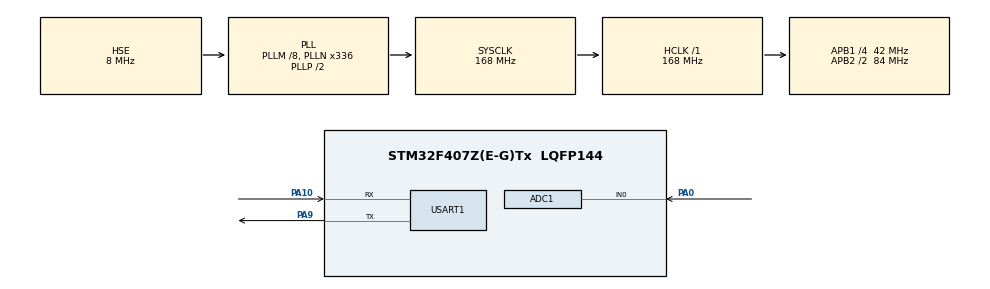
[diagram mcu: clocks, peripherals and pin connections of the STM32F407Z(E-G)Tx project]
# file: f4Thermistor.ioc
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ADC1.Channel-0\#ChannelRegularConversion=ADC_CHANNEL_0
ADC1.ContinuousConvMode=ENABLE
ADC1.DMAContinuousRequests=ENABLE
ADC1.DiscontinuousConvMode=DISABLE
ADC1.NbrOfConversion=1
ADC1.NbrOfConversionFlag=1
ADC1.Rank-0\#ChannelRegularConversion=1
ADC1.SamplingTime-0\#ChannelRegularConversion=ADC_SAMPLETIME_112CYCLES
ADC1.ScanConvMode=ENABLE
ADC1.master=1
Dma.ADC1.0.Direction=DMA_PERIPH_TO_MEMORY
Dma.ADC1.0.FIFOMode=DMA_FIFOMODE_DISABLE
Dma.ADC1.0.Instance=DMA2_Stream0
Dma.ADC1.0.MemDataAlignment=DMA_MDATAALIGN_HALFWORD
Dma.ADC1.0.MemInc=DMA_MINC_ENABLE
Dma.ADC1.0.Mode=DMA_CIRCULAR
Dma.ADC1.0.PeriphDataAlignment=DMA_PDATAALIGN_HALFWORD
Dma.ADC1.0.PeriphInc=DMA_PINC_DISABLE
Dma.ADC1.0.Priority=DMA_PRIORITY_LOW
Dma.Request0=ADC1
Mcu.Family=STM32F4
Mcu.Name=STM32F407Z(E-G)Tx
Mcu.Package=LQFP144
NVIC.DMA2_Stream0_IRQn=true\:0\:0\:false\:false\:true\:false\:true\:true
NVIC.PriorityGroup=NVIC_PRIORITYGROUP_4
PA0-WKUP.Signal=ADCx_IN0
PA10.Mode=Asynchronous
PA10.Signal=USART1_RX
PA13.Mode=Serial_Wire
PA13.Signal=SYS_JTMS-SWDIO
PA14.Mode=Serial_Wire
PA14.Signal=SYS_JTCK-SWCLK
PA9.Mode=Asynchronous
PA9.Signal=USART1_TX
PH0-OSC_IN.Mode=HSE-External-Oscillator
PH0-OSC_IN.Signal=RCC_OSC_IN
PH1-OSC_OUT.Mode=HSE-External-Oscillator
PH1-OSC_OUT.Signal=RCC_OSC_OUT
ProjectManager.HeapSize=0x200
ProjectManager.StackSize=0x400
ProjectManager.TargetToolchain=MDK-ARM V5.32
RCC.48MHZClocksFreq_Value=84000000
RCC.AHBFreq_Value=168000000
RCC.APB1CLKDivider=RCC_HCLK_DIV4
RCC.APB1Freq_Value=42000000
RCC.APB1TimFreq_Value=84000000
RCC.APB2CLKDivider=RCC_HCLK_DIV2
RCC.APB2Freq_Value=84000000
RCC.APB2TimFreq_Value=168000000
RCC.CortexFreq_Value=168000000
RCC.HCLKFreq_Value=168000000
RCC.HSE_VALUE=8000000
RCC.HSI_VALUE=16000000
RCC.LSE_VALUE=32768
RCC.PLLM=8
RCC.PLLN=336
RCC.PLLSourceVirtual=RCC_PLLSOURCE_HSE
RCC.SYSCLKFreq_VALUE=168000000
RCC.SYSCLKSource=RCC_SYSCLKSOURCE_PLLCLK
RCC.VCOOutputFreq_Value=336000000
SH.ADCx_IN0.0=ADC1_IN0,IN0
USART1.VirtualMode=VM_ASYNC
board=custom

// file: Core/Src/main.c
/* USER CODE BEGIN Header */
/**
  ******************************************************************************
  * @file           : main.c
  * @brief          : Main program body
  ******************************************************************************
  * @attention
  *
  * Copyright (c) 2026 STMicroelectronics.
  * All rights reserved.
  *
  * This software is licensed under terms that can be found in the LICENSE file
  * in the root directory of this software component.
  * If no LICENSE file comes with this software, it is provided AS-IS.
  *
  ******************************************************************************
  */
/* USER CODE END Header */
#include "main.h"
#include "adc.h"
#include "dma.h"
#include "usart.h"
#include "gpio.h"

/* USER CODE BEGIN Includes */
#include <stdint.h>
#include <stdio.h>
#include <string.h>
#include <stdlib.h>
#include "math.h"
/* USER CODE END Includes */

void SystemClock_Config(void);

/* USER CODE BEGIN 0 */
float ADC2Resistance(uint32_t adc_value)
{
  return (adc_value / (4096.0f - adc_value)) * 10000.0f;
}
/**
 * @brief 通过NTC电阻反推温度
 *
 * @param R1 NTC电阻值
 * @retval 返回温度，float类型，单位摄氏度
 */
float resistance2Temperature(float R1)
{
  float B = 3950.0f;
  float R2 = 10000.0f;
  float T2 = 25.0f;
  return (1.0 / ((1.0 / B) * log(R1 / R2) + (1.0 / (T2 + 273.15))) - 273.15);
}
/* USER CODE END 0 */

int main(void)
{

  /* MCU Configuration--------------------------------------------------------*/

  /* Reset of all peripherals, Initializes the Flash interface and the Systick. */
  HAL_Init();

  /* Configure the system clock */
  SystemClock_Config();

  /* Initialize all configured peripherals */
  MX_GPIO_Init();
  MX_DMA_Init();
  MX_ADC1_Init();
  MX_USART1_UART_Init();
  /* USER CODE BEGIN 2 */
char send_buf[100] = {0}; // 建议改大一点防溢出
volatile  uint16_t adc_result = 0;  // DMA 会自动把 ADC 的值塞进这个变量
  float ntc_resistance = 0.0f;
  float temperature = 0.0f;

  // 1. 在 while(1) 外面，开启带 DMA 的 ADC 转换！
  // 它会在后台一直默默更新 adc_result 的值
  HAL_ADC_Start_DMA(&hadc1, (uint32_t*)&adc_result, 1);
  /* USER CODE END 2 */

  /* Infinite loop */
  /* USER CODE BEGIN WHILE */
  while (1)
  {
// 2. 这里什么 ADC 操作都不用做！直接拿 adc_result 用就行
    ntc_resistance = ADC2Resistance(adc_result);
    temperature = resistance2Temperature(ntc_resistance);

    sprintf(send_buf, "阻值: %.1f Ω, 温度: %.2f ℃\r\n", ntc_resistance, temperature);
    HAL_UART_Transmit(&huart1, (uint8_t *)send_buf, strlen(send_buf), 10);

    HAL_Delay(1000);
    /* USER CODE END WHILE */

  }
}

void SystemClock_Config(void)
{
  RCC_OscInitTypeDef RCC_OscInitStruct = {0};
  RCC_ClkInitTypeDef RCC_ClkInitStruct = {0};

  /** Configure the main internal regulator output voltage
  */
  __HAL_RCC_PWR_CLK_ENABLE();
  __HAL_PWR_VOLTAGESCALING_CONFIG(PWR_REGULATOR_VOLTAGE_SCALE1);

  /** Initializes the RCC Oscillators according to the specified parameters
  * in the RCC_OscInitTypeDef structure.
  */
  RCC_OscInitStruct.OscillatorType = RCC_OSCILLATORTYPE_HSE;
  RCC_OscInitStruct.HSEState = RCC_HSE_ON;
  RCC_OscInitStruct.PLL.PLLState = RCC_PLL_ON;
  RCC_OscInitStruct.PLL.PLLSource = RCC_PLLSOURCE_HSE;
  RCC_OscInitStruct.PLL.PLLM = 8;
  RCC_OscInitStruct.PLL.PLLN = 336;
  RCC_OscInitStruct.PLL.PLLP = RCC_PLLP_DIV2;
  RCC_OscInitStruct.PLL.PLLQ = 4;
  if (HAL_RCC_OscConfig(&RCC_OscInitStruct) != HAL_OK)
  {
    Error_Handler();
  }

  /** Initializes the CPU, AHB and APB buses clocks
  */
  RCC_ClkInitStruct.ClockType = RCC_CLOCKTYPE_HCLK|RCC_CLOCKTYPE_SYSCLK
                              |RCC_CLOCKTYPE_PCLK1|RCC_CLOCKTYPE_PCLK2;
  RCC_ClkInitStruct.SYSCLKSource = RCC_SYSCLKSOURCE_PLLCLK;
  RCC_ClkInitStruct.AHBCLKDivider = RCC_SYSCLK_DIV1;
  RCC_ClkInitStruct.APB1CLKDivider = RCC_HCLK_DIV4;
  RCC_ClkInitStruct.APB2CLKDivider = RCC_HCLK_DIV2;

  if (HAL_RCC_ClockConfig(&RCC_ClkInitStruct, FLASH_LATENCY_5) != HAL_OK)
  {
    Error_Handler();
  }
}

void Error_Handler(void)
{
  __disable_irq();
  while (1)
  {
  }
}
